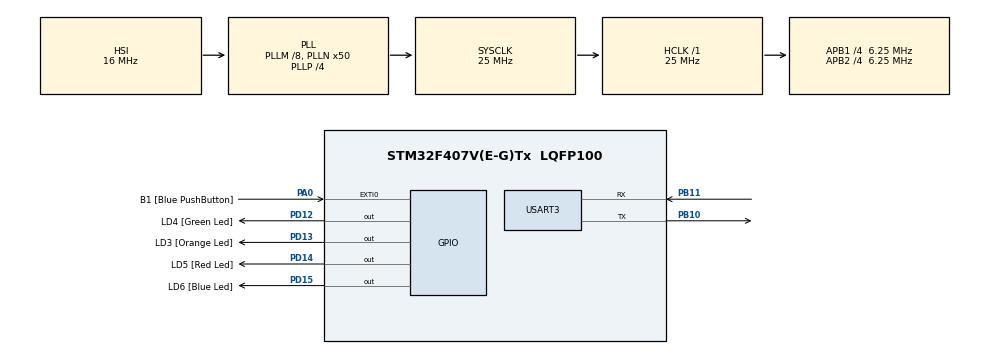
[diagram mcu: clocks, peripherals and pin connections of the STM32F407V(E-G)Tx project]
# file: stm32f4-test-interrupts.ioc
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Mcu.Family=STM32F4
Mcu.Name=STM32F407V(E-G)Tx
Mcu.Package=LQFP100
NVIC.PriorityGroup=NVIC_PRIORITYGROUP_0
NVIC.TIM7_IRQn=true\:0\:0\:false\:false\:true\:true\:true
NVIC.USART3_IRQn=true\:0\:0\:false\:false\:true\:true\:true
PA0-WKUP.GPIO_Label=B1 [Blue PushButton]
PA0-WKUP.GPIO_ModeDefaultEXTI=GPIO_MODE_EVT_RISING
PA0-WKUP.GPIO_PuPd=GPIO_NOPULL
PA0-WKUP.Signal=GPXTI0
PB10.Mode=Asynchronous
PB10.Signal=USART3_TX
PB11.Mode=Asynchronous
PB11.Signal=USART3_RX
PD12.GPIO_Label=LD4 [Green Led]
PD12.GPIO_PuPd=GPIO_NOPULL
PD12.GPIO_Speed=GPIO_SPEED_FREQ_LOW
PD12.Signal=GPIO_Output
PD13.GPIO_Label=LD3 [Orange Led]
PD13.GPIO_PuPd=GPIO_NOPULL
PD13.GPIO_Speed=GPIO_SPEED_FREQ_LOW
PD13.Signal=GPIO_Output
PD14.GPIO_Label=LD5 [Red Led]
PD14.GPIO_PuPd=GPIO_NOPULL
PD14.GPIO_Speed=GPIO_SPEED_FREQ_LOW
PD14.Signal=GPIO_Output
PD15.GPIO_Label=LD6 [Blue Led]
PD15.GPIO_PuPd=GPIO_NOPULL
PD15.GPIO_Speed=GPIO_SPEED_FREQ_LOW
PD15.Signal=GPIO_Output
ProjectManager.HeapSize=0x2000
ProjectManager.StackSize=0x4000
ProjectManager.TargetToolchain=SW4STM32
RCC.48MHZClocksFreq_Value=14285714.285714285
RCC.AHBFreq_Value=25000000
RCC.APB1CLKDivider=RCC_HCLK_DIV4
RCC.APB1Freq_Value=6250000
RCC.APB1TimFreq_Value=12500000
RCC.APB2CLKDivider=RCC_HCLK_DIV4
RCC.APB2Freq_Value=6250000
RCC.APB2TimFreq_Value=12500000
RCC.CortexFreq_Value=25000000
RCC.HCLKFreq_Value=25000000
RCC.HSE_VALUE=8000000
RCC.HSI_VALUE=16000000
RCC.LSE_VALUE=32768
RCC.PLLM=8
RCC.PLLN=50
RCC.PLLP=RCC_PLLP_DIV4
RCC.PLLQ=7
RCC.SYSCLKFreq_VALUE=25000000
RCC.SYSCLKSource=RCC_SYSCLKSOURCE_PLLCLK
RCC.VCOOutputFreq_Value=100000000
TIM7.Period=10000
TIM7.Prescaler=1249
USART3.VirtualMode=VM_ASYNC
VP_TIM7_VS_ClockSourceINT.Mode=Enable_Timer
board=STM32F4DISCOVERY

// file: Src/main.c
/* USER CODE BEGIN Header */
/**
  ******************************************************************************
  * @file           : main.c
  * @brief          : Main program body
  ******************************************************************************
  * @attention
  *
  * <h2><center>&copy; Copyright (c) 2019 STMicroelectronics.
  * All rights reserved.</center></h2>
  *
  * This software component is licensed by ST under BSD 3-Clause license,
  * the "License"; You may not use this file except in compliance with the
  * License. You may obtain a copy of the License at:
  *                        opensource.org/licenses/BSD-3-Clause
  *
  ******************************************************************************
  */
/* USER CODE END Header */

#include "main.h"

/* USER CODE BEGIN Includes */
#include "stm32f4xx_hal.h"
/* USER CODE END Includes */

TIM_HandleTypeDef htim7;

UART_HandleTypeDef huart3;

void SystemClock_Config(void);
static void MX_GPIO_Init(void);
static void MX_USART3_UART_Init(void);
static void MX_TIM7_Init(void);
/* USER CODE BEGIN PFP */
void microsecondsDelay(uint32_t);
/* USER CODE END PFP */

int main(void)
{

  /* MCU Configuration--------------------------------------------------------*/

  /* Reset of all peripherals, Initializes the Flash interface and the Systick. */
  HAL_Init();

  /* Configure the system clock */
  SystemClock_Config();

  /* Initialize all configured peripherals */
  MX_GPIO_Init();
  MX_USART3_UART_Init();
  MX_TIM7_Init();
  /* USER CODE BEGIN 2 */
  uint8_t data[100] = {};
  sprintf(data, "Start program\r\n");
  HAL_UART_Transmit(&huart3, data, 100, 0xFFFF);
  /* USER CODE END 2 */

  /* Infinite loop */
  /* USER CODE BEGIN WHILE */
  HAL_TIM_Base_Start_IT(&htim7);
  while (1)
  {
	  microsecondsDelay(1000);
    /* USER CODE END WHILE */

  }
}

void SystemClock_Config(void)
{
  RCC_OscInitTypeDef RCC_OscInitStruct = {0};
  RCC_ClkInitTypeDef RCC_ClkInitStruct = {0};

  /** Configure the main internal regulator output voltage
  */
  __HAL_RCC_PWR_CLK_ENABLE();
  __HAL_PWR_VOLTAGESCALING_CONFIG(PWR_REGULATOR_VOLTAGE_SCALE1);
  /** Initializes the CPU, AHB and APB busses clocks
  */
  RCC_OscInitStruct.OscillatorType = RCC_OSCILLATORTYPE_HSI;
  RCC_OscInitStruct.HSIState = RCC_HSI_ON;
  RCC_OscInitStruct.HSICalibrationValue = RCC_HSICALIBRATION_DEFAULT;
  RCC_OscInitStruct.PLL.PLLState = RCC_PLL_ON;
  RCC_OscInitStruct.PLL.PLLSource = RCC_PLLSOURCE_HSI;
  RCC_OscInitStruct.PLL.PLLM = 8;
  RCC_OscInitStruct.PLL.PLLN = 50;
  RCC_OscInitStruct.PLL.PLLP = RCC_PLLP_DIV4;
  RCC_OscInitStruct.PLL.PLLQ = 7;
  if (HAL_RCC_OscConfig(&RCC_OscInitStruct) != HAL_OK)
  {
    Error_Handler();
  }
  /** Initializes the CPU, AHB and APB busses clocks
  */
  RCC_ClkInitStruct.ClockType = RCC_CLOCKTYPE_HCLK|RCC_CLOCKTYPE_SYSCLK
                              |RCC_CLOCKTYPE_PCLK1|RCC_CLOCKTYPE_PCLK2;
  RCC_ClkInitStruct.SYSCLKSource = RCC_SYSCLKSOURCE_PLLCLK;
  RCC_ClkInitStruct.AHBCLKDivider = RCC_SYSCLK_DIV1;
  RCC_ClkInitStruct.APB1CLKDivider = RCC_HCLK_DIV4;
  RCC_ClkInitStruct.APB2CLKDivider = RCC_HCLK_DIV4;

  if (HAL_RCC_ClockConfig(&RCC_ClkInitStruct, FLASH_LATENCY_0) != HAL_OK)
  {
    Error_Handler();
  }
}

static void MX_TIM7_Init(void)
{

  TIM_MasterConfigTypeDef sMasterConfig = {0};

  htim7.Instance = TIM7;
  htim7.Init.Prescaler = 1249;
  htim7.Init.CounterMode = TIM_COUNTERMODE_UP;
  htim7.Init.Period = 10000;
  htim7.Init.AutoReloadPreload = TIM_AUTORELOAD_PRELOAD_DISABLE;
  if (HAL_TIM_Base_Init(&htim7) != HAL_OK)
  {
    Error_Handler();
  }
  sMasterConfig.MasterOutputTrigger = TIM_TRGO_RESET;
  sMasterConfig.MasterSlaveMode = TIM_MASTERSLAVEMODE_DISABLE;
  if (HAL_TIMEx_MasterConfigSynchronization(&htim7, &sMasterConfig) != HAL_OK)
  {
    Error_Handler();
  }

}

static void MX_USART3_UART_Init(void)
{

  huart3.Instance = USART3;
  huart3.Init.BaudRate = 115200;
  huart3.Init.WordLength = UART_WORDLENGTH_8B;
  huart3.Init.StopBits = UART_STOPBITS_1;
  huart3.Init.Parity = UART_PARITY_NONE;
  huart3.Init.Mode = UART_MODE_TX_RX;
  huart3.Init.HwFlowCtl = UART_HWCONTROL_NONE;
  huart3.Init.OverSampling = UART_OVERSAMPLING_16;
  if (HAL_UART_Init(&huart3) != HAL_OK)
  {
    Error_Handler();
  }

}

static void MX_GPIO_Init(void)
{
  GPIO_InitTypeDef GPIO_InitStruct = {0};

  /* GPIO Ports Clock Enable */
  __HAL_RCC_GPIOA_CLK_ENABLE();
  __HAL_RCC_GPIOB_CLK_ENABLE();
  __HAL_RCC_GPIOD_CLK_ENABLE();

  /*Configure GPIO pin Output Level */
  HAL_GPIO_WritePin(GPIOD, LD4_Pin|LD3_Pin|LD5_Pin|LD6_Pin, GPIO_PIN_RESET);

  /*Configure GPIO pin : B1_Pin */
  GPIO_InitStruct.Pin = B1_Pin;
  GPIO_InitStruct.Mode = GPIO_MODE_EVT_RISING;
  GPIO_InitStruct.Pull = GPIO_NOPULL;
  HAL_GPIO_Init(B1_GPIO_Port, &GPIO_InitStruct);

  /*Configure GPIO pins : LD4_Pin LD3_Pin LD5_Pin LD6_Pin */
  GPIO_InitStruct.Pin = LD4_Pin|LD3_Pin|LD5_Pin|LD6_Pin;
  GPIO_InitStruct.Mode = GPIO_MODE_OUTPUT_PP;
  GPIO_InitStruct.Pull = GPIO_NOPULL;
  GPIO_InitStruct.Speed = GPIO_SPEED_FREQ_LOW;
  HAL_GPIO_Init(GPIOD, &GPIO_InitStruct);

}

/* USER CODE BEGIN 4 */

void microsecondsDelay(uint32_t delay){
 uint32_t initTime = __HAL_TIM_GET_COUNTER(&htim7);
 while((__HAL_TIM_GET_COUNTER(&htim7) - initTime) < delay);
}

/* USER CODE END 4 */

void Error_Handler(void)
{
  /* USER CODE BEGIN Error_Handler_Debug */
  /* User can add his own implementation to report the HAL error return state */
	uint8_t error_data[100] = {};
	sprintf(error_data, "FUCKING ERROR FUCK YOU AND YOUR STM\r\n");
	HAL_UART_Transmit(&huart3, error_data, 100, 0xFFFF);
  /* USER CODE END Error_Handler_Debug */
}

/************************ (C) COPYRIGHT STMicroelectronics *****END OF FILE****/
